# nrf9120_modem register map
Vendor: Nordic Semiconductor; Series: nrf91; File version: 1
CPU: CM4 r0p1, little endian, MPU, FPU, 3 interrupt priority bits
Registers are 32-bit, read-write, reset 0x0 unless marked. A register's access mark holds for its fields unless they carry their own. Offsets are from the block's base; [hi:lo] are bit positions; {n}, {i} and the like mark numbered series.

## UICR_NS — User Information Configuration Registers
Base 0x00FF8000
0x00 APPROTECT ro reset 0xFFFFFFFF — Access Port protection
  [31:0] APPROTECT — Enable or disable Access Port protection
    0xFFFFFFFF=Disabled (Debugger access blocking disabled); 0=Enabled (Any value diferent to 0xFFFFFFFF will make debugger access blocking enabled)
0x04 ERASEPROTECT ro reset 0xFFFFFFFF — Flash erase protection
  [31:0] ERASEPROTECT — Protect against erase all and erase UICR
    0xFFFFFFFF=Disabled (Flash not protected against erase all and erase UICR); 0=Enabled (Any value diferent to 0xFFFFFFFF will make flash protected against erase all and erase UICR)
0x08 ACLREGION0ADDR ro reset 0xFFFFFFFF — ACL region0 address. Value will get inverted in the readout process before writing the value to ACL.
  [31:0] ADDR — ACL region0 address
0x0C ACLREGION0SIZE ro reset 0xFFFFFFFF — ACL region0 size. Value will get inverted in the readout process before writing the value to ACL.
  [31:0] SIZE — ACL region0 size
0x10 ACLREGION0PERM ro reset 0xFFFFFFFF — ACL region0 permissions. Value will get inverted in the readout process before writing the value to ACL.
  [2:0] PERM — ACL region0 permissions
0x14 ACLREGION1ADDR ro reset 0xFFFFFFFF — ACL region1 address. Value will get inverted in the readout process before writing the value to ACL.
  [31:0] ADDR — ACL region1 address
0x18 ACLREGION1SIZE ro reset 0xFFFFFFFF — ACL region1 size. Value will get inverted in the readout process before writing the value to ACL.
  [31:0] SIZE — ACL region1 size
0x1C ACLREGION1PERM ro reset 0xFFFFFFFF — ACL region1 permissions. Value will get inverted in the readout process before writing the value to ACL.
  [2:0] PERM — ACL region1 permissions
0x100 MDMNVMCPOFGUARD reset 0xFFFFFFFF — Enable blocking NVM WRITE and aborting NVM ERASE for LTE-Modem NVM in POFWARN condition.
  [0] NVMCPOFGUARDEN — Enable blocking NVM WRITE and aborting NVM ERASE in POFWARN condition.
    0=Disabled (NVM WRITE and NVM ERASE are not blocked in POFWARN condition.); 1=Enabled (NVM WRITE and NVM ERASE are blocked in POFWARN condition.)
0x104 PKEYREVOKED reset 0xFFFFFFFF — Private key revoked status.
  [0] REVOKED
    0=Revoked (Private key revoked and not usable anymore.); 1=Valid (Private key valid and usable.)
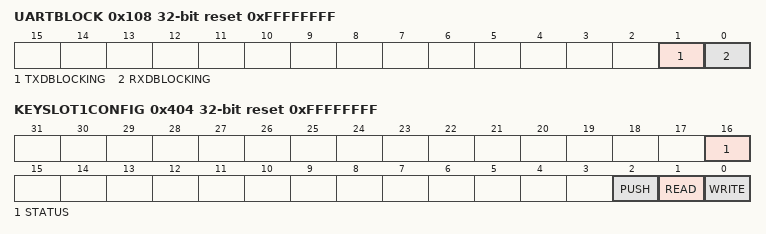
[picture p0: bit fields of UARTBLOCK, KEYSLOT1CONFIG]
0x108 UARTBLOCK reset 0xFFFFFFFF — Modem UART RXD TXD blocking.
  [1] TXDBLOCKING — TXD output blocking setting
    0=Blocked (TXD blocked, tied low.); 1=NotBlocked (TXD not blocked.)
  [0] RXDBLOCKING — RXD input blocking setting
    0=Blocked (RXD blocked, tied low.); 1=NotBlocked (RXD not blocked.)
0x400 KEYSLOT1DEST ro reset 0xFFFFFFFF — KEYSLOT1 destination address
  [31:0] DEST
0x404 KEYSLOT1CONFIG ro reset 0xFFFFFFFF — KEYSLOT1 configuration
  [16] STATUS — Key status
    0=Revoked (Key revoked); 1=Active (Key active)
  [2] PUSH — Push permission for key slot {i}
    0=Disabled (Content of registers KEYSLOT{i}.VALUE[0-3] can not be pushed, but can be read if field READ is 'Enabled'); 1=Enabled (Content of registers KEYSLOT{i}.VALUE[0-3] can be pushed over secure APB. Register KEYSLOT{i}.DEST must contain a valid destination address!)
  [1] READ — Read permission for key slot {i}.
    0=Disabled (Disable read from registers KEYSLOT{i}.VALUE[0-3]); 1=Enabled (Registers KEYSLOT{i}.VALUE[0-3] can be read)
  [0] WRITE — Write permission for key slot {i}
    0=Disabled (Disable write to registers KEYSLOT{i}.VALUE[0-3]); 1=Enabled (Registers KEYSLOT{i}.VALUE[0-3] can be written)
{0x800+4i} KEYSLOT1KEYVALUE{i} ro reset 0xFFFFFFFF (i=0..3) — KEYSLOT1 key bits [{32i+31}:{32i}]
  [31:0] VALUE

## TRACEDELAYREG_NS — Trace delay register
Base 0xD0000000
0x504 DELAY_REG_CONFIG — Configuration register for DELAY_REG delay
  [4:0] DELAY_REG_CONFIG — Register write delay, configurable between 0 and 31 clock cycles. Delay between apbPEnable and apbPReady is adjusted to the configured value, except for the small values, when minimum interconnect delay exist.
0x600 DELAY_REG wo — Dummy register with adjustable write delay. Occupies 0x100 address range i.e. 256bytes
  [31:0] DELAY_REG — Dummy register with adjustable write delay
